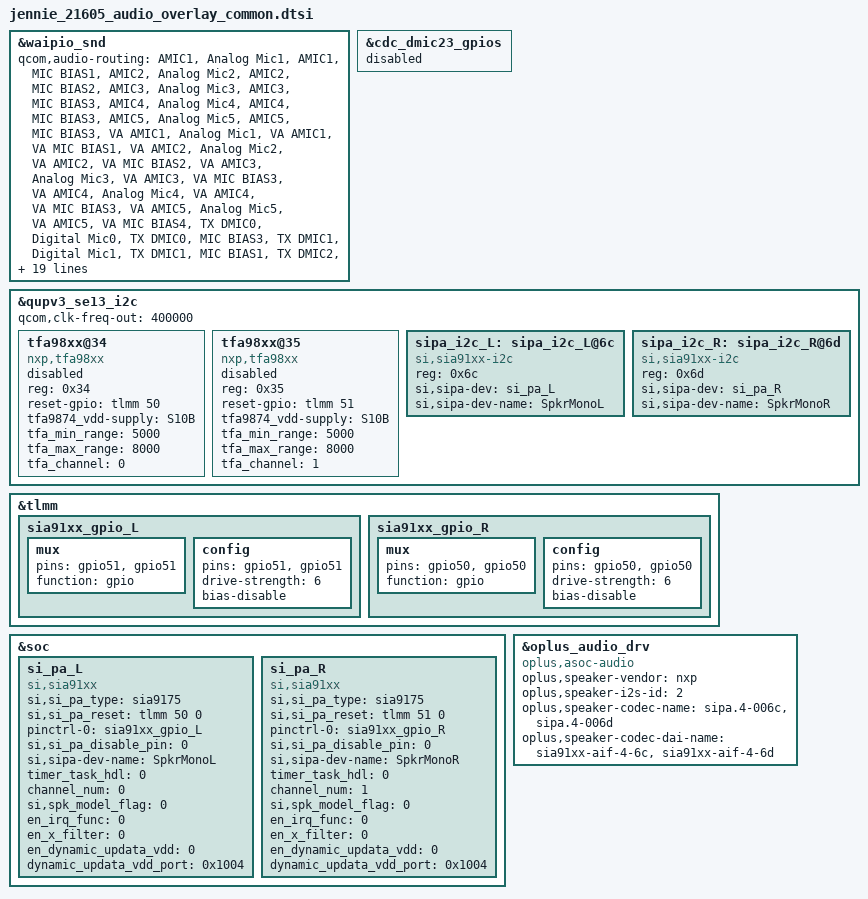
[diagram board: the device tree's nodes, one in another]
/* #ifdef OPLUS_ARCH_EXTENDS */
&waipio_snd {
        qcom,audio-routing =
                "AMIC1", "Analog Mic1",
                "AMIC1", "MIC BIAS1",
                "AMIC2", "Analog Mic2",
                "AMIC2", "MIC BIAS2",
                "AMIC3", "Analog Mic3",
                "AMIC3", "MIC BIAS3",
                "AMIC4", "Analog Mic4",
                "AMIC4", "MIC BIAS3",
                "AMIC5", "Analog Mic5",
                "AMIC5", "MIC BIAS3",
                "VA AMIC1", "Analog Mic1",
                "VA AMIC1", "VA MIC BIAS1",
                "VA AMIC2", "Analog Mic2",
                "VA AMIC2", "VA MIC BIAS2",
                "VA AMIC3", "Analog Mic3",
                "VA AMIC3", "VA MIC BIAS3",
                "VA AMIC4", "Analog Mic4",
                "VA AMIC4", "VA MIC BIAS3",
                "VA AMIC5", "Analog Mic5",
                "VA AMIC5", "VA MIC BIAS4",
                "TX DMIC0", "Digital Mic0",
                "TX DMIC0", "MIC BIAS3",
                "TX DMIC1", "Digital Mic1",
                "TX DMIC1", "MIC BIAS1",
                "TX DMIC2", "Digital Mic2",
                "TX DMIC2", "MIC BIAS1",
                "TX DMIC3", "Digital Mic3",
                "TX DMIC3", "MIC BIAS3",
                "TX DMIC4", "Digital Mic4",
                "TX DMIC4", "MIC BIAS4",
                "IN1_HPHL", "HPHL_OUT",
                "IN2_HPHR", "HPHR_OUT",
                "IN3_AUX", "AUX_OUT",
                "HAP_IN", "PCM_OUT",
                "RX_TX DEC0_INP", "TX DEC0 MUX",
                "RX_TX DEC1_INP", "TX DEC1 MUX",
                "RX_TX DEC2_INP", "TX DEC2 MUX",
                "RX_TX DEC3_INP", "TX DEC3 MUX",
                "TX SWR_INPUT", "WCD_TX_OUTPUT",
                "VA SWR_INPUT", "VA_SWR_CLK",
                "VA SWR_INPUT", "WCD_TX_OUTPUT",
                "VA_AIF1 CAP", "VA_SWR_CLK",
                "VA_AIF2 CAP", "VA_SWR_CLK",
                "VA_AIF3 CAP", "VA_SWR_CLK",
                "VA DMIC0", "Digital Mic0",
                "VA DMIC1", "Digital Mic1",
                "VA DMIC2", "Digital Mic2",
                "VA DMIC3", "Digital Mic3",
                "VA DMIC4", "Digital Mic4",
                "VA DMIC0", "VA MIC BIAS3",
                "VA DMIC1", "VA MIC BIAS1",
                "VA DMIC2", "VA MIC BIAS1",
                "VA DMIC3", "VA MIC BIAS3",
                "VA DMIC4", "VA MIC BIAS4";
          oplus,speaker-vendor = "sia91xx";
};

&cdc_dmic23_gpios {
	status = "disabled";
};

&qupv3_se13_i2c {
        status = "ok";
        qcom,clk-freq-out = <400000>;
        tfa98xx@34 {
                compatible = "nxp,tfa98xx";
                reg = <0x34>;
                reset-gpio = <&tlmm 50 0x00>;
                tfa9874_vdd-supply = <&S10B>;
                tfa_min_range = <5000>;
                tfa_max_range = <8000>;
                tfa_channel = <0>;
                status = "disabled";
        };
        tfa98xx@35 {
                compatible = "nxp,tfa98xx";
                reg = <0x35>;
                reset-gpio = <&tlmm 51 0x00>;
                tfa9874_vdd-supply = <&S10B>;
                tfa_min_range = <5000>;
                tfa_max_range = <8000>;
                tfa_channel = <1>;
                status = "disabled";
        };
        sipa_i2c_L: sipa_i2c_L@6c{
                compatible = "si,sia91xx-i2c";
                reg = <0x6c>;
                si,sipa-dev = <&si_pa_L>;
                si,sipa-dev-name = "SpkrMonoL";
        };


        sipa_i2c_R: sipa_i2c_R@6d{
                compatible = "si,sia91xx-i2c";
                reg = <0x6d>;
                si,sipa-dev = <&si_pa_R>;
                si,sipa-dev-name = "SpkrMonoR";
        };
};

&tlmm {
        sia91xx_gpio_L: sia91xx_gpio_L{
                mux {
                        pins = "gpio51", "gpio51";
                        function = "gpio";
                };

                config {
                        pins = "gpio51", "gpio51";
                        drive-strength = <6>;
                        bias-disable;
                };
        };

        sia91xx_gpio_R: sia91xx_gpio_R{
                mux {
                                pins = "gpio50", "gpio50";
                                function = "gpio";
                };

                config {
                                pins = "gpio50", "gpio50";
                                drive-strength = <6>;
                                bias-disable;
                };
        };

};

&soc {
        si_pa_L: si_pa_L{
                        compatible = "si,sia91xx";
                        si,si_pa_type = "sia9175";
                        si,si_pa_reset = <&tlmm 50 0>;
                        pinctrl-names = "si_pa_gpio";
                        pinctrl-0 = <&sia91xx_gpio_L>;
                        si,si_pa_disable_pin = <0>;
                        si,sipa-dev-name = "SpkrMonoL";
                        /* the same value share a same task
                         * valid value range : 0 ~ 7 */
                        timer_task_hdl = <0>;
                        channel_num = <0>;
                        si,spk_model_flag = <0>;
                        en_irq_func = <0>;
                        en_x_filter = <0>;
                        en_dynamic_updata_vdd = <0>;
                        dynamic_updata_vdd_port = <0x1004>;
        };

        si_pa_R: si_pa_R{
                        compatible = "si,sia91xx";
                        si,si_pa_type = "sia9175";
                        si,si_pa_reset = <&tlmm 51 0>;
                        pinctrl-names = "si_pa_gpio";
                        pinctrl-0 = <&sia91xx_gpio_R>;
                        si,si_pa_disable_pin = <0>;
                        si,sipa-dev-name = "SpkrMonoR";
                        /* the same value share a same task
                         * valid value range : 0 ~ 7 */
                        timer_task_hdl = <0>;
                        channel_num = <1>;
                        si,spk_model_flag = <0>;
                        en_irq_func = <0>;
                        en_x_filter = <0>;
                        en_dynamic_updata_vdd = <0>;
                        dynamic_updata_vdd_port = <0x1004>;
        };

};

&oplus_audio_drv {
                compatible = "oplus,asoc-audio";
                //for nxp speaker
                oplus,speaker-vendor = "nxp";
                oplus,speaker-i2s-id = <2>;
                oplus,speaker-codec-name = "sipa.4-006c", "sipa.4-006d";
                oplus,speaker-codec-dai-name = "sia91xx-aif-4-6c", "sia91xx-aif-4-6d";
};
/* OPLUS_ARCH_EXTENDS */
